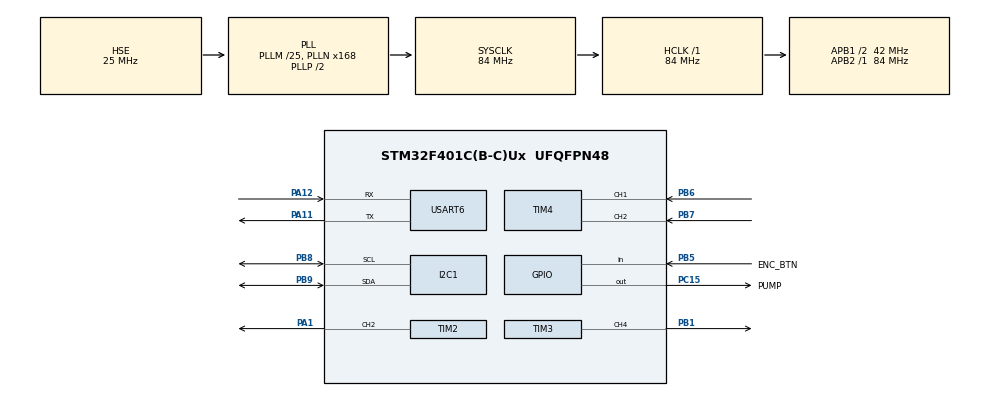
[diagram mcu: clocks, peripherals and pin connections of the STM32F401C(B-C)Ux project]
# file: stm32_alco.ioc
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Dma.Request0=TIM2_CH2/CH4
Dma.TIM2_CH2/CH4.0.Direction=DMA_PERIPH_TO_MEMORY
Dma.TIM2_CH2/CH4.0.FIFOMode=DMA_FIFOMODE_DISABLE
Dma.TIM2_CH2/CH4.0.Instance=DMA1_Stream6
Dma.TIM2_CH2/CH4.0.MemDataAlignment=DMA_MDATAALIGN_WORD
Dma.TIM2_CH2/CH4.0.MemInc=DMA_MINC_ENABLE
Dma.TIM2_CH2/CH4.0.Mode=DMA_CIRCULAR
Dma.TIM2_CH2/CH4.0.PeriphDataAlignment=DMA_PDATAALIGN_WORD
Dma.TIM2_CH2/CH4.0.PeriphInc=DMA_PINC_DISABLE
Dma.TIM2_CH2/CH4.0.Priority=DMA_PRIORITY_HIGH
FREERTOS.Queues01=queueManager,7,ManagerEvent,0,Dynamic,NULL,NULL;queueWorker,1,WorkerEvent,0,Dynamic,NULL,NULL;queueHardware,1,HardwareEvent,0,Dynamic,NULL,NULL
FREERTOS.Tasks01=defaultTask,8,128,StartDefaultTask,Default,NULL,Dynamic,NULL,NULL;taskEncoder,24,128,StartTaskEncoder,Default,NULL,Dynamic,NULL,NULL;taskDisplay,24,128,StartTaskDisplay,Default,NULL,Dynamic,NULL,NULL;taskManager,24,128,StartTaskManager,Default,NULL,Dynamic,NULL,NULL;taskWorker,24,128,StartTaskWorker,Default,NULL,Dynamic,NULL,NULL;taskHardware,24,128,StartTaskHardware,Default,NULL,Dynamic,NULL,NULL
FREERTOS.configGENERATE_RUN_TIME_STATS=1
FREERTOS.configUSE_NEWLIB_REENTRANT=1
FREERTOS.configUSE_STATS_FORMATTING_FUNCTIONS=1
Mcu.Family=STM32F4
Mcu.Name=STM32F401C(B-C)Ux
Mcu.Package=UFQFPN48
NVIC.DMA1_Stream6_IRQn=true\:5\:0\:false\:false\:true\:true\:false\:true\:true
NVIC.PriorityGroup=NVIC_PRIORITYGROUP_4
NVIC.TIM1_TRG_COM_TIM11_IRQn=true\:15\:0\:false\:false\:true\:false\:false\:true\:true
NVIC.TimeBase=TIM1_TRG_COM_TIM11_IRQn
NVIC.TimeBaseIP=TIM11
PA1.GPIO_ModeDefaultPP=GPIO_MODE_AF_OD
PA1.GPIO_Speed=GPIO_SPEED_FREQ_VERY_HIGH
PA1.Signal=S_TIM2_CH2
PA11.Mode=Asynchronous
PA11.Signal=USART6_TX
PA12.Mode=Asynchronous
PA12.Signal=USART6_RX
PA13.Mode=Serial_Wire
PA13.Signal=SYS_JTMS-SWDIO
PA14.Mode=Serial_Wire
PA14.Signal=SYS_JTCK-SWCLK
PB1.Signal=S_TIM3_CH4
PB5.GPIO_Label=ENC_BTN
PB5.GPIO_PuPd=GPIO_PULLUP
PB5.Signal=GPIO_Input
PB6.GPIO_PuPd=GPIO_PULLUP
PB6.Signal=S_TIM4_CH1
PB7.GPIO_PuPd=GPIO_PULLUP
PB7.Signal=S_TIM4_CH2
PB8.Mode=I2C
PB8.Signal=I2C1_SCL
PB9.Mode=I2C
PB9.Signal=I2C1_SDA
PC15-OSC32_OUT.GPIO_Label=PUMP
PC15-OSC32_OUT.GPIO_PuPd=GPIO_PULLUP
PC15-OSC32_OUT.Signal=GPIO_Output
PH0\ -\ OSC_IN.Mode=HSE-External-Oscillator
PH0\ -\ OSC_IN.Signal=RCC_OSC_IN
PH1\ -\ OSC_OUT.Mode=HSE-External-Oscillator
PH1\ -\ OSC_OUT.Signal=RCC_OSC_OUT
ProjectManager.HeapSize=0x200
ProjectManager.StackSize=0x400
ProjectManager.TargetToolchain=STM32CubeIDE
RCC.48MHZClocksFreq_Value=42000000
RCC.AHBFreq_Value=84000000
RCC.APB1CLKDivider=RCC_HCLK_DIV2
RCC.APB1Freq_Value=42000000
RCC.APB1TimFreq_Value=84000000
RCC.APB2Freq_Value=84000000
RCC.APB2TimFreq_Value=84000000
RCC.CortexFreq_Value=84000000
RCC.HCLKFreq_Value=84000000
RCC.HSE_VALUE=25000000
RCC.HSI_VALUE=16000000
RCC.LSE_VALUE=32768
RCC.PLLM=25
RCC.PLLN=168
RCC.PLLSourceVirtual=RCC_PLLSOURCE_HSE
RCC.SYSCLKFreq_VALUE=84000000
RCC.SYSCLKSource=RCC_SYSCLKSOURCE_PLLCLK
RCC.VCOOutputFreq_Value=168000000
SH.S_TIM2_CH2.0=TIM2_CH2,PWM Generation2 CH2
SH.S_TIM3_CH4.0=TIM3_CH4,PWM Generation4 CH4
SH.S_TIM4_CH1.0=TIM4_CH1,Encoder_Interface
SH.S_TIM4_CH2.0=TIM4_CH2,Encoder_Interface
TIM2.Channel-PWM\ Generation2\ CH2=TIM_CHANNEL_2
TIM2.Period=0xffffffff
TIM2.Prescaler=83
TIM3.Channel-PWM\ Generation4\ CH4=TIM_CHANNEL_4
TIM3.ClockDivision=TIM_CLOCKDIVISION_DIV2
TIM3.Period=19999
TIM3.Prescaler=83
TIM3.Pulse-PWM\ Generation4\ CH4=1500
USART6.VirtualMode=VM_ASYNC
VP_FREERTOS_VS_CMSIS_V2.Mode=CMSIS_V2
VP_SYS_VS_tim11.Mode=TIM11
VP_TIM10_VS_ClockSourceINT.Mode=Enable_Timer
VP_TIM2_VS_ClockSourceINT.Mode=Internal
board=custom

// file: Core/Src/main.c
/* USER CODE BEGIN Header */
/**
 ******************************************************************************
 * @file           : main.c
 * @brief          : Main program body
 ******************************************************************************
 * @attention
 *
 * Copyright (c) 2025 STMicroelectronics.
 * All rights reserved.
 *
 * This software is licensed under terms that can be found in the LICENSE file
 * in the root directory of this software component.
 * If no LICENSE file comes with this software, it is provided AS-IS.
 *
 ******************************************************************************
 */
/* USER CODE END Header */
#include "main.h"
#include "cmsis_os.h"
#include "dma.h"
#include "i2c.h"
#include "tim.h"
#include "usart.h"
#include "gpio.h"

void SystemClock_Config(void);
void MX_FREERTOS_Init(void);

int main(void)
{

  /* MCU Configuration--------------------------------------------------------*/

  /* Reset of all peripherals, Initializes the Flash interface and the Systick. */
  HAL_Init();

  /* Configure the system clock */
  SystemClock_Config();

  /* Initialize all configured peripherals */
  MX_GPIO_Init();
  MX_DMA_Init();
  MX_TIM3_Init();
  MX_TIM4_Init();
  MX_I2C1_Init();
  MX_TIM2_Init();
  MX_TIM10_Init();
  MX_USART6_UART_Init();

  /* Init scheduler */
  osKernelInitialize();

  /* Call init function for freertos objects (in cmsis_os2.c) */
  MX_FREERTOS_Init();

  /* Start scheduler */
  osKernelStart();

  /* We should never get here as control is now taken by the scheduler */

  /* Infinite loop */
  while (1) {

  }
}

void SystemClock_Config(void)
{
  RCC_OscInitTypeDef RCC_OscInitStruct = {0};
  RCC_ClkInitTypeDef RCC_ClkInitStruct = {0};

  /** Configure the main internal regulator output voltage
  */
  __HAL_RCC_PWR_CLK_ENABLE();
  __HAL_PWR_VOLTAGESCALING_CONFIG(PWR_REGULATOR_VOLTAGE_SCALE2);

  /** Initializes the RCC Oscillators according to the specified parameters
  * in the RCC_OscInitTypeDef structure.
  */
  RCC_OscInitStruct.OscillatorType = RCC_OSCILLATORTYPE_HSE;
  RCC_OscInitStruct.HSEState = RCC_HSE_ON;
  RCC_OscInitStruct.PLL.PLLState = RCC_PLL_ON;
  RCC_OscInitStruct.PLL.PLLSource = RCC_PLLSOURCE_HSE;
  RCC_OscInitStruct.PLL.PLLM = 25;
  RCC_OscInitStruct.PLL.PLLN = 168;
  RCC_OscInitStruct.PLL.PLLP = RCC_PLLP_DIV2;
  RCC_OscInitStruct.PLL.PLLQ = 4;
  if (HAL_RCC_OscConfig(&RCC_OscInitStruct) != HAL_OK)
  {
    Error_Handler();
  }

  /** Initializes the CPU, AHB and APB buses clocks
  */
  RCC_ClkInitStruct.ClockType = RCC_CLOCKTYPE_HCLK|RCC_CLOCKTYPE_SYSCLK
                              |RCC_CLOCKTYPE_PCLK1|RCC_CLOCKTYPE_PCLK2;
  RCC_ClkInitStruct.SYSCLKSource = RCC_SYSCLKSOURCE_PLLCLK;
  RCC_ClkInitStruct.AHBCLKDivider = RCC_SYSCLK_DIV1;
  RCC_ClkInitStruct.APB1CLKDivider = RCC_HCLK_DIV2;
  RCC_ClkInitStruct.APB2CLKDivider = RCC_HCLK_DIV1;

  if (HAL_RCC_ClockConfig(&RCC_ClkInitStruct, FLASH_LATENCY_2) != HAL_OK)
  {
    Error_Handler();
  }
}

/* USER CODE BEGIN 4 */
int _write(int file, char *pStr, int len) {
  uint32_t timeout = len * 10000 / 115200 + 5; // в мс (+5 мс запас)
  HAL_UART_Transmit(&huart6, (uint8_t *)pStr, len, timeout);
  return len;
}
/* USER CODE END 4 */

void HAL_TIM_PeriodElapsedCallback(TIM_HandleTypeDef *htim)
{
  if (htim->Instance == TIM11)
  {
    HAL_IncTick();
  }
}

void Error_Handler(void)
{
  __disable_irq();
  while (1) {
  }
}

#ifdef  USE_FULL_ASSERT
/**
  * @brief  Reports the name of the source file and the source line number
  *         where the assert_param error has occurred.
  * @param  file: pointer to the source file name
  * @param  line: assert_param error line source number
  * @retval None
  */
void assert_failed(uint8_t *file, uint32_t line)
{
  /* USER CODE BEGIN 6 */
  /* User can add his own implementation to report the file name and line
     number, ex: printf("Wrong parameters value: file %s on line %d\r\n", file,
     line) */
  /* USER CODE END 6 */
}
#endif /* USE_FULL_ASSERT */

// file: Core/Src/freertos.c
/* USER CODE BEGIN Header */
/**
 ******************************************************************************
 * File Name          : freertos.c
 * Description        : Code for freertos applications
 ******************************************************************************
 * @attention
 *
 * Copyright (c) 2025 STMicroelectronics.
 * All rights reserved.
 *
 * This software is licensed under terms that can be found in the LICENSE file
 * in the root directory of this software component.
 * If no LICENSE file comes with this software, it is provided AS-IS.
 *
 ******************************************************************************
 */
/* USER CODE END Header */

#include "FreeRTOS.h"
#include "task.h"
#include "main.h"
#include "cmsis_os.h"

/* USER CODE BEGIN Includes */
#include "app_shared.h"
/* USER CODE END Includes */

/* Definitions for defaultTask */
osThreadId_t defaultTaskHandle;
const osThreadAttr_t defaultTask_attributes = {
  .name = "defaultTask",
  .stack_size = 128 * 4,
  .priority = (osPriority_t) osPriorityLow,
};
/* Definitions for taskEncoder */
osThreadId_t taskEncoderHandle;
const osThreadAttr_t taskEncoder_attributes = {
  .name = "taskEncoder",
  .stack_size = 128 * 4,
  .priority = (osPriority_t) osPriorityNormal,
};
/* Definitions for taskDisplay */
osThreadId_t taskDisplayHandle;
const osThreadAttr_t taskDisplay_attributes = {
  .name = "taskDisplay",
  .stack_size = 128 * 4,
  .priority = (osPriority_t) osPriorityNormal,
};
/* Definitions for taskManager */
osThreadId_t taskManagerHandle;
const osThreadAttr_t taskManager_attributes = {
  .name = "taskManager",
  .stack_size = 128 * 4,
  .priority = (osPriority_t) osPriorityNormal,
};
/* Definitions for taskWorker */
osThreadId_t taskWorkerHandle;
const osThreadAttr_t taskWorker_attributes = {
  .name = "taskWorker",
  .stack_size = 128 * 4,
  .priority = (osPriority_t) osPriorityNormal,
};
/* Definitions for taskHardware */
osThreadId_t taskHardwareHandle;
const osThreadAttr_t taskHardware_attributes = {
  .name = "taskHardware",
  .stack_size = 128 * 4,
  .priority = (osPriority_t) osPriorityNormal,
};
/* Definitions for queueManager */
osMessageQueueId_t queueManagerHandle;
const osMessageQueueAttr_t queueManager_attributes = {
  .name = "queueManager"
};
/* Definitions for queueWorker */
osMessageQueueId_t queueWorkerHandle;
const osMessageQueueAttr_t queueWorker_attributes = {
  .name = "queueWorker"
};
/* Definitions for queueHardware */
osMessageQueueId_t queueHardwareHandle;
const osMessageQueueAttr_t queueHardware_attributes = {
  .name = "queueHardware"
};

void StartDefaultTask(void *argument);
void StartTaskEncoder(void *argument);
void StartTaskDisplay(void *argument);
void StartTaskManager(void *argument);
void StartTaskWorker(void *argument);
void StartTaskHardware(void *argument);

void MX_FREERTOS_Init(void); /* (MISRA C 2004 rule 8.1) */

/* Hook prototypes */
void configureTimerForRunTimeStats(void);
unsigned long getRunTimeCounterValue(void);

/* USER CODE BEGIN 1 */
/* Functions needed when configGENERATE_RUN_TIME_STATS is on */
extern TIM_HandleTypeDef htim2;

void configureTimerForRunTimeStats(void) { HAL_TIM_Base_Start(&htim2); }

uint32_t getRunTimeCounterValue(void) { return __HAL_TIM_GET_COUNTER(&htim2); }
/* USER CODE END 1 */

void MX_FREERTOS_Init(void) {

  /* Create the queue(s) */
  /* creation of queueManager */
  queueManagerHandle = osMessageQueueNew (7, sizeof(ManagerEvent), &queueManager_attributes);

  /* creation of queueWorker */
  queueWorkerHandle = osMessageQueueNew (1, sizeof(WorkerEvent), &queueWorker_attributes);

  /* creation of queueHardware */
  queueHardwareHandle = osMessageQueueNew (1, sizeof(HardwareEvent), &queueHardware_attributes);

  /* Create the thread(s) */
  /* creation of defaultTask */
  defaultTaskHandle = osThreadNew(StartDefaultTask, NULL, &defaultTask_attributes);

  /* creation of taskEncoder */
  taskEncoderHandle = osThreadNew(StartTaskEncoder, NULL, &taskEncoder_attributes);

  /* creation of taskDisplay */
  taskDisplayHandle = osThreadNew(StartTaskDisplay, NULL, &taskDisplay_attributes);

  /* creation of taskManager */
  taskManagerHandle = osThreadNew(StartTaskManager, NULL, &taskManager_attributes);

  /* creation of taskWorker */
  taskWorkerHandle = osThreadNew(StartTaskWorker, NULL, &taskWorker_attributes);

  /* creation of taskHardware */
  taskHardwareHandle = osThreadNew(StartTaskHardware, NULL, &taskHardware_attributes);

}

void StartDefaultTask(void *argument)
{
  for (;;) {
    osDelay(1);
  }
}

void StartTaskEncoder(void *argument)
{
  /* USER CODE BEGIN StartTaskEncoder */
  TaskEncoder(argument);
  /* Infinite loop */
  for (;;) {
    osDelay(1);
  }
  /* USER CODE END StartTaskEncoder */
}

void StartTaskDisplay(void *argument)
{
  /* USER CODE BEGIN StartTaskDisplay */
  TaskDisplay(argument);
  /* Infinite loop */
  for (;;) {
    osDelay(1);
  }
  /* USER CODE END StartTaskDisplay */
}

void StartTaskManager(void *argument)
{
  /* USER CODE BEGIN StartTaskManager */
  TaskManager(argument);
  /* Infinite loop */
  for (;;) {
    osDelay(1);
  }
  /* USER CODE END StartTaskManager */
}

void StartTaskWorker(void *argument)
{
  /* USER CODE BEGIN StartTaskWorker */
  TaskWorker(argument);
  /* Infinite loop */
  for (;;) {
    osDelay(1);
  }
  /* USER CODE END StartTaskWorker */
}

void StartTaskHardware(void *argument)
{
  for(;;)
  {
    osDelay(1);
  }
}
